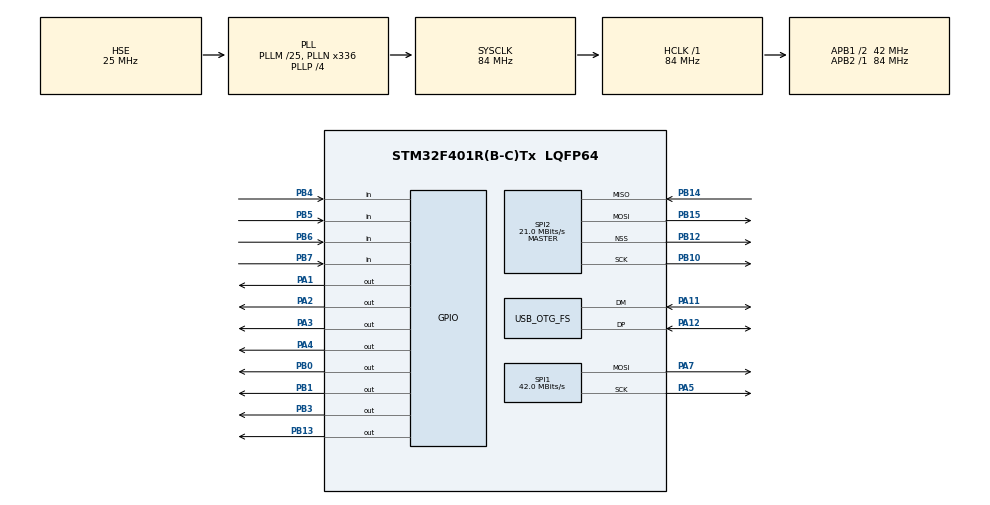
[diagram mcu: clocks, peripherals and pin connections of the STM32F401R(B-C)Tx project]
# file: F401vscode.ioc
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FREERTOS.Tasks01=defaultTask,0,128,StartDefaultTask,Default,NULL,Dynamic,NULL,NULL
FREERTOS.configENABLE_FPU=1
Mcu.Family=STM32F4
Mcu.Name=STM32F401R(B-C)Tx
Mcu.Package=LQFP64
NVIC.OTG_FS_IRQn=true\:5\:0\:false\:false\:true\:true\:false\:true\:true
NVIC.PriorityGroup=NVIC_PRIORITYGROUP_4
NVIC.TIM1_UP_TIM10_IRQn=true\:15\:0\:false\:false\:true\:false\:false\:true\:true
NVIC.TimeBase=TIM1_UP_TIM10_IRQn
NVIC.TimeBaseIP=TIM1
PA1.Signal=GPIO_Output
PA11.Mode=Device_Only
PA11.Signal=USB_OTG_FS_DM
PA12.Mode=Device_Only
PA12.Signal=USB_OTG_FS_DP
PA13.Mode=Serial_Wire
PA13.Signal=SYS_JTMS-SWDIO
PA14.Mode=Serial_Wire
PA14.Signal=SYS_JTCK-SWCLK
PA2.Signal=GPIO_Output
PA3.Signal=GPIO_Output
PA4.Signal=GPIO_Output
PA5.Mode=TX_Only_Simplex_Unidirect_Master
PA5.Signal=SPI1_SCK
PA7.Mode=TX_Only_Simplex_Unidirect_Master
PA7.Signal=SPI1_MOSI
PB0.Signal=GPIO_Output
PB1.Signal=GPIO_Output
PB10.Mode=Full_Duplex_Master
PB10.Signal=SPI2_SCK
PB12.Mode=NSS_Signal_Hard_Output
PB12.Signal=SPI2_NSS
PB13.Signal=GPIO_Output
PB14.Mode=Full_Duplex_Master
PB14.Signal=SPI2_MISO
PB15.Mode=Full_Duplex_Master
PB15.Signal=SPI2_MOSI
PB3.Signal=GPIO_Output
PB4.Signal=GPIO_Input
PB5.Signal=GPIO_Input
PB6.Signal=GPIO_Input
PB7.Signal=GPIO_Input
PH0\ -\ OSC_IN.Mode=HSE-External-Oscillator
PH0\ -\ OSC_IN.Signal=RCC_OSC_IN
PH1\ -\ OSC_OUT.Mode=HSE-External-Oscillator
PH1\ -\ OSC_OUT.Signal=RCC_OSC_OUT
ProjectManager.HeapSize=0x200
ProjectManager.StackSize=0x400
ProjectManager.TargetToolchain=Makefile
RCC.48MHZClocksFreq_Value=48000000
RCC.AHBFreq_Value=84000000
RCC.APB1CLKDivider=RCC_HCLK_DIV2
RCC.APB1Freq_Value=42000000
RCC.APB1TimFreq_Value=84000000
RCC.APB2Freq_Value=84000000
RCC.APB2TimFreq_Value=84000000
RCC.CortexFreq_Value=84000000
RCC.EnbaleCSS=true
RCC.HCLKFreq_Value=84000000
RCC.HSE_VALUE=25000000
RCC.HSI_VALUE=16000000
RCC.LSE_VALUE=32768
RCC.PLLM=25
RCC.PLLN=336
RCC.PLLP=RCC_PLLP_DIV4
RCC.PLLQ=7
RCC.SYSCLKFreq_VALUE=84000000
RCC.SYSCLKSource=RCC_SYSCLKSOURCE_PLLCLK
RCC.VCOOutputFreq_Value=336000000
SPI1.BaudRatePrescaler=SPI_BAUDRATEPRESCALER_2
SPI1.CalculateBaudRate=42.0 MBits/s
SPI1.Direction=SPI_DIRECTION_2LINES
SPI1.Mode=SPI_MODE_MASTER
SPI1.VirtualType=VM_MASTER
SPI2.BaudRatePrescaler=SPI_BAUDRATEPRESCALER_2
SPI2.CalculateBaudRate=21.0 MBits/s
SPI2.Direction=SPI_DIRECTION_2LINES
SPI2.Mode=SPI_MODE_MASTER
SPI2.VirtualNSS=VM_NSSHARD
SPI2.VirtualType=VM_MASTER
USB_DEVICE.CLASS_NAME_FS=CDC
USB_DEVICE.VirtualMode=Cdc
USB_DEVICE.VirtualModeFS=Cdc_FS
USB_OTG_FS.VirtualMode=Device_Only
VP_FREERTOS_VS_CMSIS_V1.Mode=CMSIS_V1
VP_SYS_VS_tim1.Mode=TIM1
VP_USB_DEVICE_VS_USB_DEVICE_CDC_FS.Mode=CDC_FS
board=custom

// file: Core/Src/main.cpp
/* USER CODE BEGIN Header */
/**
  ******************************************************************************
  * @file           : main.c
  * @brief          : Main program body
  ******************************************************************************
  * @attention
  *
  * Copyright (c) 2026 STMicroelectronics.
  * All rights reserved.
  *
  * This software is licensed under terms that can be found in the LICENSE file
  * in the root directory of this software component.
  * If no LICENSE file comes with this software, it is provided AS-IS.
  *
  ******************************************************************************
  */
/* USER CODE END Header */
#include "main.h"
#include "cmsis_os.h"
#include "usb_device.h"
/* USER CODE BEGIN Includes */
#include "usbd_cdc_if.h"
#include "FileUIDGenerator.hpp"
#include "ButtonControl.hpp"
#include "LcdExplorer.hpp"
#include "LcdKeyController.hpp"
#include "ButtonDrawerAnimator.hpp"
#include "NoFsStorage.hpp"
#include "CDCExchangeProtocol/CDCProtocolTransceiver.hpp"

/* USER CODE END Includes */

SPI_HandleTypeDef hspi1;
SPI_HandleTypeDef hspi2;

osThreadId defaultTaskHandle;
/* USER CODE BEGIN PV */
osThreadId cdcTxRxTaskHandle;
osThreadId cdcProcessTaskHandle;
osThreadId lcdProcessTaskHandle;
osThreadId kbdProcessTaskHandle;

CDCProtocolTransceiver _cdcProtocolTransceiver;
LcdGraphics _lcdGraphics;
LcdOutStateMachine _lcdStateMachine;
LcdExplorer _lcdExplorer(_lcdStateMachine);
ButtonDrawerAnimator _ButtonDrawerAnimator (_lcdGraphics);

W25Q128Driver _flashDevice;
NoFsStorage _noFsStorage;
FileUIDGenerator _fileUidGenerator;
ButtonControl _buttonControl;
LcdKeyController _lcdKeyController(_lcdStateMachine, _buttonControl, _ButtonDrawerAnimator);
/* USER CODE END PV */

void SystemClock_Config(void);
static void MX_GPIO_Init(void);
static void MX_SPI1_Init(void);
static void MX_SPI2_Init(void);
void StartDefaultTask(void const * argument);

/* USER CODE BEGIN PFP */
void StartCdcTxRxTask(void const * argument);
void StartCdcProcessTask(void const * argument);
void StartLcdProcessTask(void const * argument);
void StartKeyboardProcessTask(void const * argument);
/* USER CODE END PFP */

/* USER CODE BEGIN 0 */
uint8_t cfgData[512] = {
  0xAA, 0x02, 0x02, 0x03, 0x04, 0x05, 0x06, 0x07, 0x08, 0x09, 0x0A, 0x0B, 0x0C, 0x0D, 0x0E, 0x0F,
  0x10, 0x11, 0x12, 0x13, 0x14, 0x15, 0x16, 0x17, 0x18, 0x19, 0x1A, 0x1B, 0x1C, 0x1D, 0x1E, 0x1F,
  0x20, 0x21, 0x22, 0x23, 0x24, 0x25, 0x26, 0x27, 0x28, 0x29, 0x2A, 0x2B, 0x2C, 0x2D, 0x2E, 0x2F,
  0x30, 0x31, 0x32, 0x33, 0x34, 0x35, 0x36, 0x37, 0x38, 0x39, 0x3A, 0x3B, 0x3C, 0x3D, 0x3E, 0x3F,
  0x40, 0x41, 0x42, 0x43, 0x44, 0x45, 0x46, 0x47, 0x48, 0x49, 0x4A, 0x4B, 0x4C, 0x4D, 0x4E, 0x4F,
  0x50, 0x51, 0x52, 0x53, 0x54, 0x55, 0x56, 0x57, 0x58, 0x59, 0x5A, 0x5B, 0x5C, 0x5D, 0x5E, 0x5F,
  0x60, 0x61, 0x62, 0x63, 0x64, 0x65, 0x66, 0x67, 0x68, 0x69, 0x6A, 0x6B, 0x6C, 0x6D, 0x6E, 0x6F,
  0x70, 0x71, 0x72, 0x73, 0x74, 0x75, 0x76, 0x77, 0x78, 0x79, 0x7A, 0x7B, 0x7C, 0x7D, 0x7E, 0x7F,
  0x80, 0x81, 0x82, 0x83, 0x84, 0x85, 0x86, 0x87, 0x88, 0x89, 0x8A, 0x8B, 0x8C, 0x8D, 0x8E, 0x8F,
  0x90, 0x91, 0x92, 0x93, 0x94, 0x95, 0x96, 0x97, 0x98, 0x99, 0x9A, 0x9B, 0x9C, 0x9D, 0x9E, 0x9F,
  0xA0, 0xA1, 0xA2, 0xA3, 0xA4, 0xA5, 0xA6, 0xA7, 0xA8, 0xA9, 0xAA, 0xAB, 0xAC, 0xAD, 0xAE, 0xAF,
  0xB0, 0xB1, 0xB2, 0xB3, 0xB4, 0xB5, 0xB6, 0xB7, 0xB8, 0xB9, 0xBA, 0xBB, 0xBC, 0xBD, 0xBE, 0xBF,
  0xC0, 0xC1, 0xC2, 0xC3, 0xC4, 0xC5, 0xC6, 0xC7, 0xC8, 0xC9, 0xCA, 0xCB, 0xCC, 0xCD, 0xCE, 0xCF,
  0xD0, 0xD1, 0xD2, 0xD3, 0xD4, 0xD5, 0xD6, 0xD7, 0xD8, 0xD9, 0xDA, 0xDB, 0xDC, 0xDD, 0xDE, 0xDF,
  0xE0, 0xE1, 0xE2, 0xE3, 0xE4, 0xE5, 0xE6, 0xE7, 0xE8, 0xE9, 0xEA, 0xEB, 0xEC, 0xED, 0xEE, 0xEF,
  0xF0, 0xF1, 0xF2, 0xF3, 0xF4, 0xF5, 0xF6, 0xF7, 0xF8, 0xF9, 0xFA, 0xFB, 0xFC, 0xFD, 0xFE, 0xFF
};

void Test() {
  //size_t cfgSize = 512;
  //uint8_t packetSize = 64;
  //uint8_t* pCfgData = (uint8_t*)cfgData;

  /*uint8_t res = _noFsStorage.Init();

  uint32_t uid = _fileUidGenerator.GetNewUid();

  res = _noFsStorage.StartNewCfgRecord(uid, cfgSize);
  uint8_t iterations = cfgSize / packetSize;
  if(cfgSize % packetSize) {
    iterations++;
  }

  for (uint8_t i = 0; i < iterations; i++) {
    res = _noFsStorage.WriteCfgRecordNextPart(pCfgData, packetSize);
    pCfgData += packetSize;
  }

  etl::array<uint32_t, MAX_FILES_NUMBER> files = _noFsStorage.GetFileUids();
  for (uint8_t i = MAX_FILES_NUMBER - 1; i > 0; i--) {
      _noFsStorage.DeleteRecord(files.at(i));
  }*/
  return;
}
/* USER CODE END 0 */

int main(void) {

  /* MCU Configuration--------------------------------------------------------*/

  /* Reset of all peripherals, Initializes the Flash interface and the Systick. */
  HAL_Init();

  /* Configure the system clock */
  SystemClock_Config();

  /* Initialize all configured peripherals */
  MX_GPIO_Init();
  MX_SPI1_Init();
  MX_SPI2_Init();
  /* USER CODE BEGIN 2 */
  Test();

  _noFsStorage.Init();
  _lcdExplorer.Init();

  /* USER CODE END 2 */

  /* Create the thread(s) */
  /* definition and creation of defaultTask */
  osThreadDef(defaultTask, StartDefaultTask, osPriorityNormal, 0, 128);
  defaultTaskHandle = osThreadCreate(osThread(defaultTask), NULL);

  /* USER CODE BEGIN RTOS_THREADS */
  /* add threads, ... */
  osThreadDef(cdcTxRxTask, StartCdcTxRxTask, osPriorityNormal, 0, 128);
  cdcTxRxTaskHandle = osThreadCreate(osThread(cdcTxRxTask), NULL);

  osThreadDef(cdcProcessTask, StartCdcProcessTask, osPriorityNormal, 0, 128);
  cdcProcessTaskHandle = osThreadCreate(osThread(cdcProcessTask), NULL);

  osThreadDef(lcdProcessTask, StartLcdProcessTask, osPriorityNormal, 0, 448);
  lcdProcessTaskHandle = osThreadCreate(osThread(lcdProcessTask), NULL);

  osThreadDef(kbdProcessTask, StartKeyboardProcessTask, osPriorityNormal, 0, 128);
  kbdProcessTaskHandle = osThreadCreate(osThread(kbdProcessTask), NULL);

  /* USER CODE END RTOS_THREADS */

  /* Start scheduler */
  osKernelStart();

  /* We should never get here as control is now taken by the scheduler */

  /* Infinite loop */
  while (1) {

  }
}

void SystemClock_Config(void)
{
  RCC_OscInitTypeDef RCC_OscInitStruct = {0};
  RCC_ClkInitTypeDef RCC_ClkInitStruct = {0};

  /** Configure the main internal regulator output voltage
  */
  __HAL_RCC_PWR_CLK_ENABLE();
  __HAL_PWR_VOLTAGESCALING_CONFIG(PWR_REGULATOR_VOLTAGE_SCALE2);

  /** Initializes the RCC Oscillators according to the specified parameters
  * in the RCC_OscInitTypeDef structure.
  */
  RCC_OscInitStruct.OscillatorType = RCC_OSCILLATORTYPE_HSE;
  RCC_OscInitStruct.HSEState = RCC_HSE_ON;
  RCC_OscInitStruct.PLL.PLLState = RCC_PLL_ON;
  RCC_OscInitStruct.PLL.PLLSource = RCC_PLLSOURCE_HSE;
  RCC_OscInitStruct.PLL.PLLM = 25;
  RCC_OscInitStruct.PLL.PLLN = 336;
  RCC_OscInitStruct.PLL.PLLP = RCC_PLLP_DIV4;
  RCC_OscInitStruct.PLL.PLLQ = 7;
  if (HAL_RCC_OscConfig(&RCC_OscInitStruct) != HAL_OK)
  {
    Error_Handler();
  }

  /** Initializes the CPU, AHB and APB buses clocks
  */
  RCC_ClkInitStruct.ClockType = RCC_CLOCKTYPE_HCLK|RCC_CLOCKTYPE_SYSCLK
                              |RCC_CLOCKTYPE_PCLK1|RCC_CLOCKTYPE_PCLK2;
  RCC_ClkInitStruct.SYSCLKSource = RCC_SYSCLKSOURCE_PLLCLK;
  RCC_ClkInitStruct.AHBCLKDivider = RCC_SYSCLK_DIV1;
  RCC_ClkInitStruct.APB1CLKDivider = RCC_HCLK_DIV2;
  RCC_ClkInitStruct.APB2CLKDivider = RCC_HCLK_DIV1;

  if (HAL_RCC_ClockConfig(&RCC_ClkInitStruct, FLASH_LATENCY_2) != HAL_OK)
  {
    Error_Handler();
  }

  /** Enables the Clock Security System
  */
  HAL_RCC_EnableCSS();
}

static void MX_SPI1_Init(void) {

  /* SPI1 parameter configuration*/
  hspi1.Instance = SPI1;
  hspi1.Init.Mode = SPI_MODE_MASTER;
  hspi1.Init.Direction = SPI_DIRECTION_2LINES;
  hspi1.Init.DataSize = SPI_DATASIZE_8BIT;
  hspi1.Init.CLKPolarity = SPI_POLARITY_LOW;
  hspi1.Init.CLKPhase = SPI_PHASE_1EDGE;
  hspi1.Init.NSS = SPI_NSS_SOFT;
  hspi1.Init.BaudRatePrescaler = SPI_BAUDRATEPRESCALER_2;
  hspi1.Init.FirstBit = SPI_FIRSTBIT_MSB;
  hspi1.Init.TIMode = SPI_TIMODE_DISABLE;
  hspi1.Init.CRCCalculation = SPI_CRCCALCULATION_DISABLE;
  hspi1.Init.CRCPolynomial = 10;
  if (HAL_SPI_Init(&hspi1) != HAL_OK)
  {
    Error_Handler();
  }

}

static void MX_SPI2_Init(void) {

  /* SPI2 parameter configuration*/
  hspi2.Instance = SPI2;
  hspi2.Init.Mode = SPI_MODE_MASTER;
  hspi2.Init.Direction = SPI_DIRECTION_2LINES;
  hspi2.Init.DataSize = SPI_DATASIZE_8BIT;
  hspi2.Init.CLKPolarity = SPI_POLARITY_LOW;
  hspi2.Init.CLKPhase = SPI_PHASE_1EDGE;
  hspi2.Init.NSS = SPI_NSS_SOFT;
  hspi2.Init.BaudRatePrescaler = SPI_BAUDRATEPRESCALER_4;
  hspi2.Init.FirstBit = SPI_FIRSTBIT_MSB;
  hspi2.Init.TIMode = SPI_TIMODE_DISABLE;
  hspi2.Init.CRCCalculation = SPI_CRCCALCULATION_DISABLE;
  hspi2.Init.CRCPolynomial = 10;
  if (HAL_SPI_Init(&hspi2) != HAL_OK) {
    Error_Handler();
  }

}

static void MX_GPIO_Init(void) {
  GPIO_InitTypeDef GPIO_InitStruct = {0};

  /* GPIO Ports Clock Enable */
  __HAL_RCC_GPIOC_CLK_ENABLE();
  __HAL_RCC_GPIOD_CLK_ENABLE();
  __HAL_RCC_GPIOA_CLK_ENABLE();
  __HAL_RCC_GPIOB_CLK_ENABLE();

  /*Configure GPIO pin Output Level */
  HAL_GPIO_WritePin(GPIOA, GPIO_PIN_9, GPIO_PIN_RESET);
  HAL_GPIO_WritePin(GPIOA, GPIO_PIN_1|GPIO_PIN_2|GPIO_PIN_3|GPIO_PIN_4, GPIO_PIN_RESET);

  HAL_GPIO_WritePin(GPIOC, GPIO_PIN_13, GPIO_PIN_RESET);

  /*Configure GPIO pin Output Level */
  HAL_GPIO_WritePin(GPIOB, GPIO_PIN_0|GPIO_PIN_1|GPIO_PIN_3, GPIO_PIN_RESET);

  /*Configure GPIO pins : PA1 PA2 PA3 PA4 - outputs for keyboard matrix*/
  GPIO_InitStruct.Pin = GPIO_PIN_1|GPIO_PIN_2|GPIO_PIN_3|GPIO_PIN_4;
  GPIO_InitStruct.Mode = GPIO_MODE_OUTPUT_PP;
  GPIO_InitStruct.Pull = GPIO_PULLUP;
  GPIO_InitStruct.Speed = GPIO_SPEED_FREQ_LOW;
  HAL_GPIO_Init(GPIOA, &GPIO_InitStruct);

  /*Configure GPIO pin : PC13 */
  GPIO_InitStruct.Pin = GPIO_PIN_13;
  GPIO_InitStruct.Mode = GPIO_MODE_OUTPUT_PP;
  GPIO_InitStruct.Pull = GPIO_NOPULL;
  GPIO_InitStruct.Speed = GPIO_SPEED_FREQ_LOW;
  HAL_GPIO_Init(GPIOC, &GPIO_InitStruct);

  /*Configure GPIO pins : PB0 PB1 PB3 */
  GPIO_InitStruct.Pin = GPIO_PIN_0|GPIO_PIN_1|GPIO_PIN_3;
  GPIO_InitStruct.Mode = GPIO_MODE_OUTPUT_PP;
  GPIO_InitStruct.Pull = GPIO_NOPULL;
  GPIO_InitStruct.Speed = GPIO_SPEED_FREQ_LOW;
  HAL_GPIO_Init(GPIOB, &GPIO_InitStruct);

  /*Configure GPIO pins : PB4 PB5 PB6 PB7 - inputs for keyboard matrix*/
  GPIO_InitStruct.Pin = GPIO_PIN_4|GPIO_PIN_5|GPIO_PIN_6|GPIO_PIN_7;
  GPIO_InitStruct.Mode = GPIO_MODE_INPUT;
  GPIO_InitStruct.Pull = GPIO_PULLUP;
  HAL_GPIO_Init(GPIOB, &GPIO_InitStruct);

  /* USER CODE BEGIN MX_GPIO_Init_2 */
  GPIO_InitStruct.Pin = GPIO_PIN_9;
  GPIO_InitStruct.Mode = GPIO_MODE_OUTPUT_PP;
  GPIO_InitStruct.Pull = GPIO_NOPULL;
  GPIO_InitStruct.Speed = GPIO_SPEED_FREQ_HIGH;
  HAL_GPIO_Init(GPIOA, &GPIO_InitStruct);
  HAL_GPIO_WritePin(GPIOA, GPIO_PIN_9, GPIO_PIN_SET);
  /* USER CODE END MX_GPIO_Init_2 */
}

void StartDefaultTask(void const * argument) {
  /* init code for USB_DEVICE */
  MX_USB_DEVICE_Init();
  /* USER CODE BEGIN 5 */
  /* Infinite loop */
  for(;;) {
   HAL_GPIO_TogglePin(GPIOC, GPIO_PIN_13);
   osDelay(500);
  }
  /* USER CODE END 5 */
}

/* USER CODE BEGIN 6 */
void StartCdcTxRxTask(void const * argument) {
  for(;;) {
    _cdcProtocolTransceiver.Receive();
    _cdcProtocolTransceiver.Transmit();
  }
}

void StartCdcProcessTask(void const * argument) {
  for(;;) {
    _cdcProtocolTransceiver.Process();
  }
}

void StartLcdProcessTask(void const * argument) {
  for(;;) {
    _lcdExplorer.ProcessLcdState();
  }
}

void StartKeyboardProcessTask(void const * argument) {
  for(;;) {
    _lcdKeyController.Step();
  }
}
 /* USER CODE END 6 */

void HAL_TIM_PeriodElapsedCallback(TIM_HandleTypeDef *htim) {
  if (htim->Instance == TIM1)
  {
    HAL_IncTick();
  }
}

void Error_Handler(void) {
  __disable_irq();
  while (1) {
  }
}
